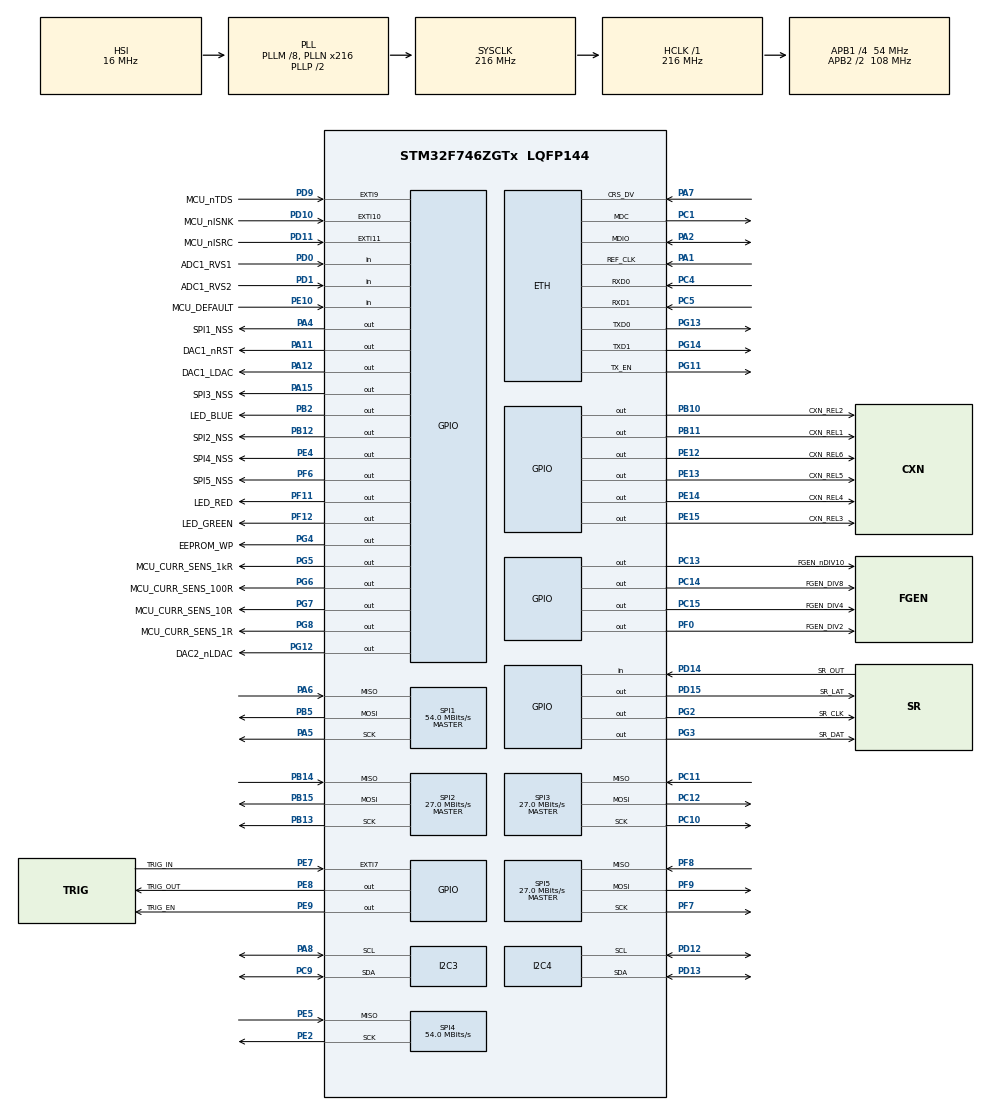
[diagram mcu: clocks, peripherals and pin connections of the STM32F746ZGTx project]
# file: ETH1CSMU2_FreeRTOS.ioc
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CORTEX_M7.CPU_DCache=Disabled
CORTEX_M7.CPU_ICache=Disabled
CORTEX_M7.MPU_Control=__NULL
Dma.Request0=SPI4_RX
Dma.SPI4_RX.0.Direction=DMA_PERIPH_TO_MEMORY
Dma.SPI4_RX.0.FIFOMode=DMA_FIFOMODE_DISABLE
Dma.SPI4_RX.0.Instance=DMA2_Stream0
Dma.SPI4_RX.0.MemDataAlignment=DMA_MDATAALIGN_HALFWORD
Dma.SPI4_RX.0.MemInc=DMA_MINC_ENABLE
Dma.SPI4_RX.0.Mode=DMA_NORMAL
Dma.SPI4_RX.0.PeriphDataAlignment=DMA_PDATAALIGN_HALFWORD
Dma.SPI4_RX.0.PeriphInc=DMA_PINC_DISABLE
Dma.SPI4_RX.0.Priority=DMA_PRIORITY_HIGH
ETH.MediaInterface=HAL_ETH_RMII_MODE
FREERTOS.Queues01=QueueLED,1,uint8_t,0,Static,QueueLEDBuffer,QueueLEDControlBlock;QueueTrigger,1,uint8_t,0,Dynamic,NULL,NULL
FREERTOS.Tasks01=defaultTask,24,254,StartDefaultTask,Default,NULL,Dynamic,NULL,NULL;LEDTask,8,128,StartLEDTask,Default,NULL,Dynamic,NULL,NULL;TriggerTask,8,254,StartTriggerTask,Default,NULL,Dynamic,NULL,NULL
FREERTOS.configENABLE_FPU=1
FREERTOS.configGENERATE_RUN_TIME_STATS=1
FREERTOS.configMINIMAL_STACK_SIZE=128
FREERTOS.configTIMER_TASK_STACK_DEPTH=254
FREERTOS.configTOTAL_HEAP_SIZE=60000
FREERTOS.configUSE_NEWLIB_REENTRANT=1
FREERTOS.configUSE_STATS_FORMATTING_FUNCTIONS=1
I2C3.Timing=0x20404768
I2C4.Timing=0x20404768
LWIP.BSP.number=1
LWIP.CMSIS_VERSION-Enabled=1
LWIP.DEFAULT_THREAD_STACKSIZE=2048
LWIP.GATEWAY_ADDRESS=192.168.001.001
LWIP.IP_ADDRESS=192.168.001.130
LWIP.LWIP_DBG_MIN_LEVEL=LWIP_DBG_LEVEL_ALL
LWIP.LWIP_DHCP=0
LWIP.MEM_SIZE=3200
LWIP.NETMASK_ADDRESS=255.255.255.000
LWIP.TCPIP_THREAD_STACKSIZE=2048
LWIP.Version=v2.1.2_Cube
LWIP0.BSP.STBoard=false
LWIP0.BSP.api=BSP_COMPONENT_DRIVER
LWIP0.BSP.component=LAN8742
LWIP0.BSP.instance=LAN8742
LWIP0.BSP.name=Driver_PHY
LWIP0.BSP.semaphore=S_LAN8742
LWIP0.BSP.solution=LAN8742
Mcu.Family=STM32F7
Mcu.Name=STM32F746ZGTx
Mcu.Package=LQFP144
NVIC.DMA2_Stream0_IRQn=true\:5\:0\:false\:false\:true\:true\:false\:true\:true
NVIC.ETH_IRQn=true\:5\:0\:false\:false\:true\:true\:false\:true\:true
NVIC.PriorityGroup=NVIC_PRIORITYGROUP_4
NVIC.TIM2_IRQn=true\:0\:0\:true\:false\:true\:false\:false\:true\:true
NVIC.TimeBase=TIM2_IRQn
NVIC.TimeBaseIP=TIM2
PA1.Mode=RMII
PA1.Signal=ETH_REF_CLK
PA11.GPIO_Label=DAC1_nRST
PA11.PinState=GPIO_PIN_SET
PA11.Signal=GPIO_Output
PA12.GPIO_Label=DAC1_LDAC
PA12.Signal=GPIO_Output
PA13.Mode=Serial_Wire
PA13.Signal=SYS_JTMS-SWDIO
PA14.Mode=Serial_Wire
PA14.Signal=SYS_JTCK-SWCLK
PA15.GPIO_Label=SPI3_NSS
PA15.PinState=GPIO_PIN_SET
PA15.Signal=GPIO_Output
PA2.Mode=RMII
PA2.Signal=ETH_MDIO
PA4.GPIO_Label=SPI1_NSS
PA4.PinState=GPIO_PIN_SET
PA4.Signal=GPIO_Output
PA5.GPIO_Speed=GPIO_SPEED_FREQ_HIGH
PA5.Mode=Full_Duplex_Master
PA5.Signal=SPI1_SCK
PA6.GPIO_Speed=GPIO_SPEED_FREQ_HIGH
PA6.Mode=Full_Duplex_Master
PA6.Signal=SPI1_MISO
PA7.Mode=RMII
PA7.Signal=ETH_CRS_DV
PA8.Mode=I2C
PA8.Signal=I2C3_SCL
PB10.GPIO_Label=CXN_REL2
PB10.GPIO_Speed=GPIO_SPEED_FREQ_MEDIUM
PB10.PinState=GPIO_PIN_RESET
PB10.Signal=GPIO_Output
PB11.GPIO_Label=CXN_REL1
PB11.GPIO_Speed=GPIO_SPEED_FREQ_MEDIUM
PB11.PinState=GPIO_PIN_RESET
PB11.Signal=GPIO_Output
PB12.GPIO_Label=SPI2_NSS
PB12.PinState=GPIO_PIN_SET
PB12.Signal=GPIO_Output
PB13.Mode=Full_Duplex_Master
PB13.Signal=SPI2_SCK
PB14.Mode=Full_Duplex_Master
PB14.Signal=SPI2_MISO
PB15.Mode=Full_Duplex_Master
PB15.Signal=SPI2_MOSI
PB2.GPIO_Label=LED_BLUE
PB2.PinState=GPIO_PIN_SET
PB2.Signal=GPIO_Output
PB5.GPIO_Speed=GPIO_SPEED_FREQ_HIGH
PB5.Mode=Full_Duplex_Master
PB5.Signal=SPI1_MOSI
PC1.Mode=RMII
PC1.Signal=ETH_MDC
PC10.GPIO_PuPd=GPIO_PULLUP
PC10.GPIO_Speed=GPIO_SPEED_FREQ_HIGH
PC10.Mode=Full_Duplex_Master
PC10.Signal=SPI3_SCK
PC11.GPIO_Speed=GPIO_SPEED_FREQ_HIGH
PC11.Mode=Full_Duplex_Master
PC11.Signal=SPI3_MISO
PC12.GPIO_Speed=GPIO_SPEED_FREQ_HIGH
PC12.Mode=Full_Duplex_Master
PC12.Signal=SPI3_MOSI
PC13.GPIO_Label=FGEN_nDIV10
PC13.PinState=GPIO_PIN_SET
PC13.Signal=GPIO_Output
PC14/OSC32_IN.GPIO_Label=FGEN_DIV8
PC14/OSC32_IN.PinState=GPIO_PIN_SET
PC14/OSC32_IN.Signal=GPIO_Output
PC15/OSC32_OUT.GPIO_Label=FGEN_DIV4
PC15/OSC32_OUT.PinState=GPIO_PIN_SET
PC15/OSC32_OUT.Signal=GPIO_Output
PC4.Mode=RMII
PC4.Signal=ETH_RXD0
PC5.Mode=RMII
PC5.Signal=ETH_RXD1
PC9.Mode=I2C
PC9.Signal=I2C3_SDA
PD0.GPIO_Label=ADC1_RVS1
PD0.Signal=GPIO_Input
PD1.GPIO_Label=ADC1_RVS2
PD1.Signal=GPIO_Input
PD10.GPIO_Label=MCU_nISNK
PD10.Signal=GPXTI10
PD11.GPIO_Label=MCU_nISRC
PD11.Signal=GPXTI11
PD12.Mode=I2C
PD12.Signal=I2C4_SCL
PD13.Mode=I2C
PD13.Signal=I2C4_SDA
PD14.GPIO_Label=SR_OUT
PD14.Signal=GPIO_Input
PD15.GPIO_Label=SR_LAT
PD15.Signal=GPIO_Output
PD9.GPIO_Label=MCU_nTDS
PD9.Signal=GPXTI9
PE10.GPIO_Label=MCU_DEFAULT
PE10.Signal=GPIO_Input
PE12.GPIO_Label=CXN_REL6
PE12.GPIO_Speed=GPIO_SPEED_FREQ_MEDIUM
PE12.Signal=GPIO_Output
PE13.GPIO_Label=CXN_REL5
PE13.GPIO_Speed=GPIO_SPEED_FREQ_MEDIUM
PE13.Signal=GPIO_Output
PE14.GPIO_Label=CXN_REL4
PE14.GPIO_Speed=GPIO_SPEED_FREQ_MEDIUM
PE14.Signal=GPIO_Output
PE15.GPIO_Label=CXN_REL3
PE15.GPIO_Speed=GPIO_SPEED_FREQ_MEDIUM
PE15.Signal=GPIO_Output
PE2.Mode=RX_Only_Simplex_Unidirect_Master
PE2.Signal=SPI4_SCK
PE4.GPIO_Label=SPI4_NSS
PE4.PinState=GPIO_PIN_RESET
PE4.Signal=GPIO_Output
PE5.Mode=RX_Only_Simplex_Unidirect_Master
PE5.Signal=SPI4_MISO
PE7.GPIO_Label=TRIG_IN
PE7.Signal=GPXTI7
PE8.GPIO_Label=TRIG_OUT
PE8.Signal=GPIO_Output
PE9.GPIO_Label=TRIG_EN
PE9.Signal=GPIO_Output
PF0.GPIO_Label=FGEN_DIV2
PF0.PinState=GPIO_PIN_SET
PF0.Signal=GPIO_Output
PF11.GPIO_Label=LED_RED
PF11.PinState=GPIO_PIN_SET
PF11.Signal=GPIO_Output
PF12.GPIO_Label=LED_GREEN
PF12.PinState=GPIO_PIN_SET
PF12.Signal=GPIO_Output
PF6.GPIO_Label=SPI5_NSS
PF6.GPIO_Speed=GPIO_SPEED_FREQ_HIGH
PF6.PinState=GPIO_PIN_SET
PF6.Signal=GPIO_Output
PF7.Mode=Full_Duplex_Master
PF7.Signal=SPI5_SCK
PF8.Mode=Full_Duplex_Master
PF8.Signal=SPI5_MISO
PF9.Mode=Full_Duplex_Master
PF9.Signal=SPI5_MOSI
PG11.Mode=RMII
PG11.Signal=ETH_TX_EN
PG12.GPIO_Label=DAC2_nLDAC
PG12.GPIO_Speed=GPIO_SPEED_FREQ_HIGH
PG12.PinState=GPIO_PIN_SET
PG12.Signal=GPIO_Output
PG13.Mode=RMII
PG13.Signal=ETH_TXD0
PG14.Mode=RMII
PG14.Signal=ETH_TXD1
PG2.GPIO_Label=SR_CLK
PG2.Signal=GPIO_Output
PG3.GPIO_Label=SR_DAT
PG3.Signal=GPIO_Output
PG4.GPIO_Label=EEPROM_WP
PG4.PinState=GPIO_PIN_SET
PG4.Signal=GPIO_Output
PG5.GPIO_Label=MCU_CURR_SENS_1kR
PG5.Signal=GPIO_Output
PG6.GPIO_Label=MCU_CURR_SENS_100R
PG6.PinState=GPIO_PIN_RESET
PG6.Signal=GPIO_Output
PG7.GPIO_Label=MCU_CURR_SENS_10R
PG7.PinState=GPIO_PIN_RESET
PG7.Signal=GPIO_Output
PG8.GPIO_Label=MCU_CURR_SENS_1R
PG8.PinState=GPIO_PIN_SET
PG8.Signal=GPIO_Output
ProjectManager.HeapSize=0x200
ProjectManager.StackSize=0x400
ProjectManager.TargetToolchain=STM32CubeIDE
RCC.AHBFreq_Value=216000000
RCC.APB1CLKDivider=RCC_HCLK_DIV4
RCC.APB1Freq_Value=54000000
RCC.APB1TimFreq_Value=108000000
RCC.APB2CLKDivider=RCC_HCLK_DIV2
RCC.APB2Freq_Value=108000000
RCC.APB2TimFreq_Value=216000000
RCC.CortexFreq_Value=216000000
RCC.HCLKFreq_Value=216000000
RCC.HSE_VALUE=8000000
RCC.HSI_VALUE=16000000
RCC.LSE_VALUE=32768
RCC.PLLM=8
RCC.PLLN=216
RCC.SYSCLKFreq_VALUE=216000000
RCC.SYSCLKSource=RCC_SYSCLKSOURCE_PLLCLK
RCC.USBFreq_Value=216000000
RCC.VCOOutputFreq_Value=432000000
SPI1.BaudRatePrescaler=SPI_BAUDRATEPRESCALER_2
SPI1.CLKPolarity=SPI_POLARITY_LOW
SPI1.CalculateBaudRate=54.0 MBits/s
SPI1.DataSize=SPI_DATASIZE_16BIT
SPI1.Direction=SPI_DIRECTION_2LINES
SPI1.Mode=SPI_MODE_MASTER
SPI1.VirtualType=VM_MASTER
SPI2.BaudRatePrescaler=SPI_BAUDRATEPRESCALER_2
SPI2.CLKPhase=SPI_PHASE_1EDGE
SPI2.CLKPolarity=SPI_POLARITY_HIGH
SPI2.CalculateBaudRate=27.0 MBits/s
SPI2.DataSize=SPI_DATASIZE_8BIT
SPI2.Direction=SPI_DIRECTION_2LINES
SPI2.Mode=SPI_MODE_MASTER
SPI2.VirtualType=VM_MASTER
SPI3.BaudRatePrescaler=SPI_BAUDRATEPRESCALER_2
SPI3.CLKPolarity=SPI_POLARITY_HIGH
SPI3.CalculateBaudRate=27.0 MBits/s
SPI3.DataSize=SPI_DATASIZE_16BIT
SPI3.Direction=SPI_DIRECTION_2LINES
SPI3.Mode=SPI_MODE_MASTER
SPI3.VirtualType=VM_MASTER
SPI4.BaudRatePrescaler=SPI_BAUDRATEPRESCALER_2
SPI4.CLKPhase=SPI_PHASE_1EDGE
SPI4.CalculateBaudRate=54.0 MBits/s
SPI4.DataSize=SPI_DATASIZE_16BIT
SPI4.Direction=SPI_DIRECTION_2LINES_RXONLY
SPI4.Mode=SPI_MODE_MASTER
SPI4.VirtualType=VM_MASTER
SPI5.BaudRatePrescaler=SPI_BAUDRATEPRESCALER_4
SPI5.CalculateBaudRate=27.0 MBits/s
SPI5.DataSize=SPI_DATASIZE_16BIT
SPI5.Direction=SPI_DIRECTION_2LINES
SPI5.Mode=SPI_MODE_MASTER
SPI5.VirtualType=VM_MASTER
TIM3.Period=0xffff -1
TIM3.Prescaler=216 -1
VP_FREERTOS_VS_CMSIS_V2.Mode=CMSIS_V2
VP_LWIP_VS_Enabled.Mode=Enabled
VP_SYS_VS_tim2.Mode=TIM2
VP_TIM3_VS_ClockSourceINT.Mode=Internal
board=custom

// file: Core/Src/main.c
/* USER CODE BEGIN Header */
/**
  ******************************************************************************
  * @file           : main.c
  * @brief          : Main program body
  ******************************************************************************
  * @attention
  *
  * Copyright (c) 2022 STMicroelectronics.
  * All rights reserved.
  *
  * This software is licensed under terms that can be found in the LICENSE file
  * in the root directory of this software component.
  * If no LICENSE file comes with this software, it is provided AS-IS.
  *
  ******************************************************************************
  */
/* USER CODE END Header */
#include "main.h"
#include "cmsis_os.h"
#include "lwip.h"

/* USER CODE BEGIN Includes */
#include "LED.h"
#include "74HC595.h"
#include "AD9834.h"
#include "MAX5217.h"
#include "DAC8565.h"
#include "ADS8681.h"
#include "FGEN.h"
#include "SCPI_Server.h"
#include "Delay.h"
/* USER CODE END Includes */

typedef StaticQueue_t osStaticMessageQDef_t;

I2C_HandleTypeDef hi2c3;
I2C_HandleTypeDef hi2c4;

SPI_HandleTypeDef hspi1;
SPI_HandleTypeDef hspi2;
SPI_HandleTypeDef hspi3;
SPI_HandleTypeDef hspi4;
SPI_HandleTypeDef hspi5;
DMA_HandleTypeDef hdma_spi4_rx;

TIM_HandleTypeDef htim3;

/* Definitions for defaultTask */
osThreadId_t defaultTaskHandle;
const osThreadAttr_t defaultTask_attributes = {
  .name = "defaultTask",
  .stack_size = 254 * 4,
  .priority = (osPriority_t) osPriorityNormal,
};
/* Definitions for LEDTask */
osThreadId_t LEDTaskHandle;
const osThreadAttr_t LEDTask_attributes = {
  .name = "LEDTask",
  .stack_size = 128 * 4,
  .priority = (osPriority_t) osPriorityLow,
};
/* Definitions for TriggerTask */
osThreadId_t TriggerTaskHandle;
const osThreadAttr_t TriggerTask_attributes = {
  .name = "TriggerTask",
  .stack_size = 254 * 4,
  .priority = (osPriority_t) osPriorityLow,
};
/* Definitions for QueueLED */
osMessageQueueId_t QueueLEDHandle;
uint8_t QueueLEDBuffer[ 1 * sizeof( uint8_t ) ];
osStaticMessageQDef_t QueueLEDControlBlock;
const osMessageQueueAttr_t QueueLED_attributes = {
  .name = "QueueLED",
  .cb_mem = &QueueLEDControlBlock,
  .cb_size = sizeof(QueueLEDControlBlock),
  .mq_mem = &QueueLEDBuffer,
  .mq_size = sizeof(QueueLEDBuffer)
};
/* Definitions for QueueTrigger */
osMessageQueueId_t QueueTriggerHandle;
const osMessageQueueAttr_t QueueTrigger_attributes = {
  .name = "QueueTrigger"
};
/* USER CODE BEGIN PV */
extern uint8_t shiftRegisters[];
extern struct bsp_t bsp;
/* USER CODE END PV */

void SystemClock_Config(void);
static void MX_GPIO_Init(void);
static void MX_DMA_Init(void);
static void MX_SPI3_Init(void);
static void MX_SPI4_Init(void);
static void MX_SPI5_Init(void);
static void MX_I2C3_Init(void);
static void MX_I2C4_Init(void);
static void MX_SPI1_Init(void);
static void MX_SPI2_Init(void);
static void MX_TIM3_Init(void);
void StartDefaultTask(void *argument);
void StartLEDTask(void *argument);
void StartTriggerTask(void *argument);

int main(void)
{

  /* MCU Configuration--------------------------------------------------------*/

  /* Reset of all peripherals, Initializes the Flash interface and the Systick. */
  HAL_Init();

  /* Configure the system clock */
  SystemClock_Config();

  /* Initialize all configured peripherals */
  MX_GPIO_Init();
  SN74HC595_Init();
  MX_DMA_Init();
  MX_SPI3_Init();
  MX_SPI4_Init();
  MX_SPI5_Init();
  MX_I2C3_Init();
  MX_I2C4_Init();
  MX_SPI1_Init();
  MX_SPI2_Init();
  MX_TIM3_Init();
  /* USER CODE BEGIN 2 */
  DAC8565_Init();
  TIM_DelayInit();
  BSP_Init();
  //SN74HC595_Init();
  MAX5217_Init();
  ADS8681_Init();
  FGEN_Init();

  TIM_DelayInit();
//  AD9834_Init();
  /* USER CODE END 2 */

  /* Init scheduler */
  osKernelInitialize();

  /* Create the queue(s) */
  /* creation of QueueLED */
  QueueLEDHandle = osMessageQueueNew (1, sizeof(uint8_t), &QueueLED_attributes);

  /* creation of QueueTrigger */
  QueueTriggerHandle = osMessageQueueNew (1, sizeof(uint8_t), &QueueTrigger_attributes);

  /* Create the thread(s) */
  /* creation of defaultTask */
 // defaultTaskHandle = osThreadNew(StartDefaultTask, NULL, &defaultTask_attributes);

  /* creation of LEDTask */
  LEDTaskHandle = osThreadNew(StartLEDTask, NULL, &LEDTask_attributes);

  /* creation of TriggerTask */
  TriggerTaskHandle = osThreadNew(StartTriggerTask, NULL, &TriggerTask_attributes);

  /* USER CODE BEGIN RTOS_THREADS */
  /* add threads, ... */
  MX_LWIP_Init();
  scpi_server_init();
  /* USER CODE END RTOS_THREADS */

  /* Start scheduler */
  osKernelStart();
  /* We should never get here as control is now taken by the scheduler */
  /* Infinite loop */
  while (1)
  {

  }
}

void SystemClock_Config(void)
{
  RCC_OscInitTypeDef RCC_OscInitStruct = {0};
  RCC_ClkInitTypeDef RCC_ClkInitStruct = {0};

  /** Configure the main internal regulator output voltage
  */
  __HAL_RCC_PWR_CLK_ENABLE();
  __HAL_PWR_VOLTAGESCALING_CONFIG(PWR_REGULATOR_VOLTAGE_SCALE1);

  /** Initializes the RCC Oscillators according to the specified parameters
  * in the RCC_OscInitTypeDef structure.
  */
  RCC_OscInitStruct.OscillatorType = RCC_OSCILLATORTYPE_HSI;
  RCC_OscInitStruct.HSIState = RCC_HSI_ON;
  RCC_OscInitStruct.HSICalibrationValue = RCC_HSICALIBRATION_DEFAULT;
  RCC_OscInitStruct.PLL.PLLState = RCC_PLL_ON;
  RCC_OscInitStruct.PLL.PLLSource = RCC_PLLSOURCE_HSI;
  RCC_OscInitStruct.PLL.PLLM = 8;
  RCC_OscInitStruct.PLL.PLLN = 216;
  RCC_OscInitStruct.PLL.PLLP = RCC_PLLP_DIV2;
  RCC_OscInitStruct.PLL.PLLQ = 2;
  if (HAL_RCC_OscConfig(&RCC_OscInitStruct) != HAL_OK)
  {
    Error_Handler();
  }

  /** Activate the Over-Drive mode
  */
  if (HAL_PWREx_EnableOverDrive() != HAL_OK)
  {
    Error_Handler();
  }

  /** Initializes the CPU, AHB and APB buses clocks
  */
  RCC_ClkInitStruct.ClockType = RCC_CLOCKTYPE_HCLK|RCC_CLOCKTYPE_SYSCLK
                              |RCC_CLOCKTYPE_PCLK1|RCC_CLOCKTYPE_PCLK2;
  RCC_ClkInitStruct.SYSCLKSource = RCC_SYSCLKSOURCE_PLLCLK;
  RCC_ClkInitStruct.AHBCLKDivider = RCC_SYSCLK_DIV1;
  RCC_ClkInitStruct.APB1CLKDivider = RCC_HCLK_DIV4;
  RCC_ClkInitStruct.APB2CLKDivider = RCC_HCLK_DIV2;

  if (HAL_RCC_ClockConfig(&RCC_ClkInitStruct, FLASH_LATENCY_7) != HAL_OK)
  {
    Error_Handler();
  }
}

static void MX_I2C3_Init(void)
{

  hi2c3.Instance = I2C3;
  hi2c3.Init.Timing = 0x20404768;
  hi2c3.Init.OwnAddress1 = 0;
  hi2c3.Init.AddressingMode = I2C_ADDRESSINGMODE_7BIT;
  hi2c3.Init.DualAddressMode = I2C_DUALADDRESS_DISABLE;
  hi2c3.Init.OwnAddress2 = 0;
  hi2c3.Init.OwnAddress2Masks = I2C_OA2_NOMASK;
  hi2c3.Init.GeneralCallMode = I2C_GENERALCALL_DISABLE;
  hi2c3.Init.NoStretchMode = I2C_NOSTRETCH_DISABLE;
  if (HAL_I2C_Init(&hi2c3) != HAL_OK)
  {
    Error_Handler();
  }

  /** Configure Analogue filter
  */
  if (HAL_I2CEx_ConfigAnalogFilter(&hi2c3, I2C_ANALOGFILTER_ENABLE) != HAL_OK)
  {
    Error_Handler();
  }

  /** Configure Digital filter
  */
  if (HAL_I2CEx_ConfigDigitalFilter(&hi2c3, 0) != HAL_OK)
  {
    Error_Handler();
  }

}

static void MX_I2C4_Init(void)
{

  hi2c4.Instance = I2C4;
  hi2c4.Init.Timing = 0x20404768;
  hi2c4.Init.OwnAddress1 = 0;
  hi2c4.Init.AddressingMode = I2C_ADDRESSINGMODE_7BIT;
  hi2c4.Init.DualAddressMode = I2C_DUALADDRESS_DISABLE;
  hi2c4.Init.OwnAddress2 = 0;
  hi2c4.Init.OwnAddress2Masks = I2C_OA2_NOMASK;
  hi2c4.Init.GeneralCallMode = I2C_GENERALCALL_DISABLE;
  hi2c4.Init.NoStretchMode = I2C_NOSTRETCH_DISABLE;
  if (HAL_I2C_Init(&hi2c4) != HAL_OK)
  {
    Error_Handler();
  }

  /** Configure Analogue filter
  */
  if (HAL_I2CEx_ConfigAnalogFilter(&hi2c4, I2C_ANALOGFILTER_ENABLE) != HAL_OK)
  {
    Error_Handler();
  }

  /** Configure Digital filter
  */
  if (HAL_I2CEx_ConfigDigitalFilter(&hi2c4, 0) != HAL_OK)
  {
    Error_Handler();
  }

}

static void MX_SPI1_Init(void)
{

  /* SPI1 parameter configuration*/
  hspi1.Instance = SPI1;
  hspi1.Init.Mode = SPI_MODE_MASTER;
  hspi1.Init.Direction = SPI_DIRECTION_2LINES;
  hspi1.Init.DataSize = SPI_DATASIZE_16BIT;
  hspi1.Init.CLKPolarity = SPI_POLARITY_LOW;
  hspi1.Init.CLKPhase = SPI_PHASE_1EDGE;
  hspi1.Init.NSS = SPI_NSS_SOFT;
  hspi1.Init.BaudRatePrescaler = SPI_BAUDRATEPRESCALER_2;
  hspi1.Init.FirstBit = SPI_FIRSTBIT_MSB;
  hspi1.Init.TIMode = SPI_TIMODE_DISABLE;
  hspi1.Init.CRCCalculation = SPI_CRCCALCULATION_DISABLE;
  hspi1.Init.CRCPolynomial = 7;
  hspi1.Init.CRCLength = SPI_CRC_LENGTH_DATASIZE;
  hspi1.Init.NSSPMode = SPI_NSS_PULSE_ENABLE;
  if (HAL_SPI_Init(&hspi1) != HAL_OK)
  {
    Error_Handler();
  }

}

static void MX_SPI2_Init(void)
{

  /* SPI2 parameter configuration*/
  hspi2.Instance = SPI2;
  hspi2.Init.Mode = SPI_MODE_MASTER;
  hspi2.Init.Direction = SPI_DIRECTION_2LINES;
  hspi2.Init.DataSize = SPI_DATASIZE_8BIT;
  hspi2.Init.CLKPolarity = SPI_POLARITY_HIGH;
  hspi2.Init.CLKPhase = SPI_PHASE_1EDGE;
  hspi2.Init.NSS = SPI_NSS_SOFT;
  hspi2.Init.BaudRatePrescaler = SPI_BAUDRATEPRESCALER_2;
  hspi2.Init.FirstBit = SPI_FIRSTBIT_MSB;
  hspi2.Init.TIMode = SPI_TIMODE_DISABLE;
  hspi2.Init.CRCCalculation = SPI_CRCCALCULATION_DISABLE;
  hspi2.Init.CRCPolynomial = 7;
  hspi2.Init.CRCLength = SPI_CRC_LENGTH_DATASIZE;
  hspi2.Init.NSSPMode = SPI_NSS_PULSE_ENABLE;
  if (HAL_SPI_Init(&hspi2) != HAL_OK)
  {
    Error_Handler();
  }

}

static void MX_SPI3_Init(void)
{

  /* SPI3 parameter configuration*/
  hspi3.Instance = SPI3;
  hspi3.Init.Mode = SPI_MODE_MASTER;
  hspi3.Init.Direction = SPI_DIRECTION_2LINES;
  hspi3.Init.DataSize = SPI_DATASIZE_16BIT;
  hspi3.Init.CLKPolarity = SPI_POLARITY_HIGH;
  hspi3.Init.CLKPhase = SPI_PHASE_1EDGE;
  hspi3.Init.NSS = SPI_NSS_SOFT;
  hspi3.Init.BaudRatePrescaler = SPI_BAUDRATEPRESCALER_2;
  hspi3.Init.FirstBit = SPI_FIRSTBIT_MSB;
  hspi3.Init.TIMode = SPI_TIMODE_DISABLE;
  hspi3.Init.CRCCalculation = SPI_CRCCALCULATION_DISABLE;
  hspi3.Init.CRCPolynomial = 7;
  hspi3.Init.CRCLength = SPI_CRC_LENGTH_DATASIZE;
  hspi3.Init.NSSPMode = SPI_NSS_PULSE_ENABLE;
  if (HAL_SPI_Init(&hspi3) != HAL_OK)
  {
    Error_Handler();
  }

}

static void MX_SPI4_Init(void)
{

  /* SPI4 parameter configuration*/
  hspi4.Instance = SPI4;
  hspi4.Init.Mode = SPI_MODE_MASTER;
  hspi4.Init.Direction = SPI_DIRECTION_2LINES_RXONLY;
  hspi4.Init.DataSize = SPI_DATASIZE_16BIT;
  hspi4.Init.CLKPolarity = SPI_POLARITY_LOW;
  hspi4.Init.CLKPhase = SPI_PHASE_1EDGE;
  hspi4.Init.NSS = SPI_NSS_SOFT;
  hspi4.Init.BaudRatePrescaler = SPI_BAUDRATEPRESCALER_2;
  hspi4.Init.FirstBit = SPI_FIRSTBIT_MSB;
  hspi4.Init.TIMode = SPI_TIMODE_DISABLE;
  hspi4.Init.CRCCalculation = SPI_CRCCALCULATION_DISABLE;
  hspi4.Init.CRCPolynomial = 7;
  hspi4.Init.CRCLength = SPI_CRC_LENGTH_DATASIZE;
  hspi4.Init.NSSPMode = SPI_NSS_PULSE_ENABLE;
  if (HAL_SPI_Init(&hspi4) != HAL_OK)
  {
    Error_Handler();
  }

}

static void MX_SPI5_Init(void)
{

  /* SPI5 parameter configuration*/
  hspi5.Instance = SPI5;
  hspi5.Init.Mode = SPI_MODE_MASTER;
  hspi5.Init.Direction = SPI_DIRECTION_2LINES;
  hspi5.Init.DataSize = SPI_DATASIZE_16BIT;
  hspi5.Init.CLKPolarity = SPI_POLARITY_LOW;
  hspi5.Init.CLKPhase = SPI_PHASE_1EDGE;
  hspi5.Init.NSS = SPI_NSS_SOFT;
  hspi5.Init.BaudRatePrescaler = SPI_BAUDRATEPRESCALER_4;
  hspi5.Init.FirstBit = SPI_FIRSTBIT_MSB;
  hspi5.Init.TIMode = SPI_TIMODE_DISABLE;
  hspi5.Init.CRCCalculation = SPI_CRCCALCULATION_DISABLE;
  hspi5.Init.CRCPolynomial = 7;
  hspi5.Init.CRCLength = SPI_CRC_LENGTH_DATASIZE;
  hspi5.Init.NSSPMode = SPI_NSS_PULSE_ENABLE;
  if (HAL_SPI_Init(&hspi5) != HAL_OK)
  {
    Error_Handler();
  }

}

static void MX_TIM3_Init(void)
{

  TIM_ClockConfigTypeDef sClockSourceConfig = {0};
  TIM_MasterConfigTypeDef sMasterConfig = {0};

  htim3.Instance = TIM3;
  htim3.Init.Prescaler = 216 -1;
  htim3.Init.CounterMode = TIM_COUNTERMODE_UP;
  htim3.Init.Period = 0xffff -1;
  htim3.Init.ClockDivision = TIM_CLOCKDIVISION_DIV1;
  htim3.Init.AutoReloadPreload = TIM_AUTORELOAD_PRELOAD_DISABLE;
  if (HAL_TIM_Base_Init(&htim3) != HAL_OK)
  {
    Error_Handler();
  }
  sClockSourceConfig.ClockSource = TIM_CLOCKSOURCE_INTERNAL;
  if (HAL_TIM_ConfigClockSource(&htim3, &sClockSourceConfig) != HAL_OK)
  {
    Error_Handler();
  }
  sMasterConfig.MasterOutputTrigger = TIM_TRGO_RESET;
  sMasterConfig.MasterSlaveMode = TIM_MASTERSLAVEMODE_DISABLE;
  if (HAL_TIMEx_MasterConfigSynchronization(&htim3, &sMasterConfig) != HAL_OK)
  {
    Error_Handler();
  }

}

static void MX_DMA_Init(void)
{

  /* DMA controller clock enable */
  __HAL_RCC_DMA2_CLK_ENABLE();

  /* DMA interrupt init */
  /* DMA2_Stream0_IRQn interrupt configuration */
  HAL_NVIC_SetPriority(DMA2_Stream0_IRQn, 5, 0);
  HAL_NVIC_EnableIRQ(DMA2_Stream0_IRQn);

}

static void MX_GPIO_Init(void)
{
  LL_EXTI_InitTypeDef EXTI_InitStruct = {0};
  LL_GPIO_InitTypeDef GPIO_InitStruct = {0};

  /* GPIO Ports Clock Enable */
  LL_AHB1_GRP1_EnableClock(LL_AHB1_GRP1_PERIPH_GPIOE);
  LL_AHB1_GRP1_EnableClock(LL_AHB1_GRP1_PERIPH_GPIOC);
  LL_AHB1_GRP1_EnableClock(LL_AHB1_GRP1_PERIPH_GPIOF);
  LL_AHB1_GRP1_EnableClock(LL_AHB1_GRP1_PERIPH_GPIOA);
  LL_AHB1_GRP1_EnableClock(LL_AHB1_GRP1_PERIPH_GPIOB);
  LL_AHB1_GRP1_EnableClock(LL_AHB1_GRP1_PERIPH_GPIOD);
  LL_AHB1_GRP1_EnableClock(LL_AHB1_GRP1_PERIPH_GPIOG);

  /**/
  LL_GPIO_ResetOutputPin(SPI4_NSS_GPIO_Port, SPI4_NSS_Pin);

  /**/
  LL_GPIO_ResetOutputPin(TRIG_OUT_GPIO_Port, TRIG_OUT_Pin);

  /**/
  LL_GPIO_ResetOutputPin(TRIG_EN_GPIO_Port, TRIG_EN_Pin);

  /**/
  LL_GPIO_ResetOutputPin(CXN_REL6_GPIO_Port, CXN_REL6_Pin);

  /**/
  LL_GPIO_ResetOutputPin(CXN_REL5_GPIO_Port, CXN_REL5_Pin);

  /**/
  LL_GPIO_ResetOutputPin(CXN_REL4_GPIO_Port, CXN_REL4_Pin);

  /**/
  LL_GPIO_ResetOutputPin(CXN_REL3_GPIO_Port, CXN_REL3_Pin);

  /**/
  LL_GPIO_ResetOutputPin(CXN_REL2_GPIO_Port, CXN_REL2_Pin);

  /**/
  LL_GPIO_ResetOutputPin(CXN_REL1_GPIO_Port, CXN_REL1_Pin);

  /**/
  LL_GPIO_ResetOutputPin(SR_LAT_GPIO_Port, SR_LAT_Pin);

  /**/
  LL_GPIO_ResetOutputPin(SR_CLK_GPIO_Port, SR_CLK_Pin);

  /**/
  LL_GPIO_ResetOutputPin(SR_DAT_GPIO_Port, SR_DAT_Pin);

  /**/
  LL_GPIO_ResetOutputPin(MCU_CURR_SENS_1kR_GPIO_Port, MCU_CURR_SENS_1kR_Pin);

  /**/
  LL_GPIO_ResetOutputPin(MCU_CURR_SENS_100R_GPIO_Port, MCU_CURR_SENS_100R_Pin);

  /**/
  LL_GPIO_ResetOutputPin(MCU_CURR_SENS_10R_GPIO_Port, MCU_CURR_SENS_10R_Pin);

  /**/
  LL_GPIO_ResetOutputPin(DAC1_LDAC_GPIO_Port, DAC1_LDAC_Pin);

  /**/
  LL_GPIO_SetOutputPin(FGEN_nDIV10_GPIO_Port, FGEN_nDIV10_Pin);

  /**/
  LL_GPIO_SetOutputPin(FGEN_DIV8_GPIO_Port, FGEN_DIV8_Pin);

  /**/
  LL_GPIO_SetOutputPin(FGEN_DIV4_GPIO_Port, FGEN_DIV4_Pin);

  /**/
  LL_GPIO_SetOutputPin(FGEN_DIV2_GPIO_Port, FGEN_DIV2_Pin);

  /**/
  LL_GPIO_SetOutputPin(SPI5_NSS_GPIO_Port, SPI5_NSS_Pin);

  /**/
  LL_GPIO_SetOutputPin(SPI1_NSS_GPIO_Port, SPI1_NSS_Pin);

  /**/
  LL_GPIO_SetOutputPin(LED_BLUE_GPIO_Port, LED_BLUE_Pin);

  /**/
  LL_GPIO_SetOutputPin(LED_RED_GPIO_Port, LED_RED_Pin);

  /**/
  LL_GPIO_SetOutputPin(LED_GREEN_GPIO_Port, LED_GREEN_Pin);

  /**/
  LL_GPIO_SetOutputPin(SPI2_NSS_GPIO_Port, SPI2_NSS_Pin);

  /**/
  LL_GPIO_SetOutputPin(EEPROM_WP_GPIO_Port, EEPROM_WP_Pin);

  /**/
  LL_GPIO_SetOutputPin(MCU_CURR_SENS_1R_GPIO_Port, MCU_CURR_SENS_1R_Pin);

  /**/
  LL_GPIO_SetOutputPin(DAC1_nRST_GPIO_Port, DAC1_nRST_Pin);

  /**/
  LL_GPIO_SetOutputPin(SPI3_NSS_GPIO_Port, SPI3_NSS_Pin);

  /**/
  LL_GPIO_SetOutputPin(DAC2_nLDAC_GPIO_Port, DAC2_nLDAC_Pin);

  /**/
  GPIO_InitStruct.Pin = SPI4_NSS_Pin;
  GPIO_InitStruct.Mode = LL_GPIO_MODE_OUTPUT;
  GPIO_InitStruct.Speed = LL_GPIO_SPEED_FREQ_LOW;
  GPIO_InitStruct.OutputType = LL_GPIO_OUTPUT_PUSHPULL;
  GPIO_InitStruct.Pull = LL_GPIO_PULL_NO;
  LL_GPIO_Init(SPI4_NSS_GPIO_Port, &GPIO_InitStruct);

  /**/
  GPIO_InitStruct.Pin = FGEN_nDIV10_Pin;
  GPIO_InitStruct.Mode = LL_GPIO_MODE_OUTPUT;
  GPIO_InitStruct.Speed = LL_GPIO_SPEED_FREQ_LOW;
  GPIO_InitStruct.OutputType = LL_GPIO_OUTPUT_PUSHPULL;
  GPIO_InitStruct.Pull = LL_GPIO_PULL_NO;
  LL_GPIO_Init(FGEN_nDIV10_GPIO_Port, &GPIO_InitStruct);

  /**/
  GPIO_InitStruct.Pin = FGEN_DIV8_Pin;
  GPIO_InitStruct.Mode = LL_GPIO_MODE_OUTPUT;
  GPIO_InitStruct.Speed = LL_GPIO_SPEED_FREQ_LOW;
  GPIO_InitStruct.OutputType = LL_GPIO_OUTPUT_PUSHPULL;
  GPIO_InitStruct.Pull = LL_GPIO_PULL_NO;
  LL_GPIO_Init(FGEN_DIV8_GPIO_Port, &GPIO_InitStruct);

  /**/
  GPIO_InitStruct.Pin = FGEN_DIV4_Pin;
  GPIO_InitStruct.Mode = LL_GPIO_MODE_OUTPUT;
  GPIO_InitStruct.Speed = LL_GPIO_SPEED_FREQ_LOW;
  GPIO_InitStruct.OutputType = LL_GPIO_OUTPUT_PUSHPULL;
  GPIO_InitStruct.Pull = LL_GPIO_PULL_NO;
  LL_GPIO_Init(FGEN_DIV4_GPIO_Port, &GPIO_InitStruct);

  /**/
  GPIO_InitStruct.Pin = FGEN_DIV2_Pin;
  GPIO_InitStruct.Mode = LL_GPIO_MODE_OUTPUT;
  GPIO_InitStruct.Speed = LL_GPIO_SPEED_FREQ_LOW;
  GPIO_InitStruct.OutputType = LL_GPIO_OUTPUT_PUSHPULL;
  GPIO_InitStruct.Pull = LL_GPIO_PULL_NO;
  LL_GPIO_Init(FGEN_DIV2_GPIO_Port, &GPIO_InitStruct);

  /**/
  GPIO_InitStruct.Pin = SPI5_NSS_Pin;
  GPIO_InitStruct.Mode = LL_GPIO_MODE_OUTPUT;
  GPIO_InitStruct.Speed = LL_GPIO_SPEED_FREQ_HIGH;
  GPIO_InitStruct.OutputType = LL_GPIO_OUTPUT_PUSHPULL;
  GPIO_InitStruct.Pull = LL_GPIO_PULL_NO;
  LL_GPIO_Init(SPI5_NSS_GPIO_Port, &GPIO_InitStruct);

  /**/
  GPIO_InitStruct.Pin = SPI1_NSS_Pin;
  GPIO_InitStruct.Mode = LL_GPIO_MODE_OUTPUT;
  GPIO_InitStruct.Speed = LL_GPIO_SPEED_FREQ_LOW;
  GPIO_InitStruct.OutputType = LL_GPIO_OUTPUT_PUSHPULL;
  GPIO_InitStruct.Pull = LL_GPIO_PULL_NO;
  LL_GPIO_Init(SPI1_NSS_GPIO_Port, &GPIO_InitStruct);

  /**/
  GPIO_InitStruct.Pin = LED_BLUE_Pin;
  GPIO_InitStruct.Mode = LL_GPIO_MODE_OUTPUT;
  GPIO_InitStruct.Speed = LL_GPIO_SPEED_FREQ_LOW;
  GPIO_InitStruct.OutputType = LL_GPIO_OUTPUT_PUSHPULL;
  GPIO_InitStruct.Pull = LL_GPIO_PULL_NO;
  LL_GPIO_Init(LED_BLUE_GPIO_Port, &GPIO_InitStruct);

  /**/
  GPIO_InitStruct.Pin = LED_RED_Pin;
  GPIO_InitStruct.Mode = LL_GPIO_MODE_OUTPUT;
  GPIO_InitStruct.Speed = LL_GPIO_SPEED_FREQ_LOW;
  GPIO_InitStruct.OutputType = LL_GPIO_OUTPUT_PUSHPULL;
  GPIO_InitStruct.Pull = LL_GPIO_PULL_NO;
  LL_GPIO_Init(LED_RED_GPIO_Port, &GPIO_InitStruct);

  /**/
  GPIO_InitStruct.Pin = LED_GREEN_Pin;
  GPIO_InitStruct.Mode = LL_GPIO_MODE_OUTPUT;
  GPIO_InitStruct.Speed = LL_GPIO_SPEED_FREQ_LOW;
  GPIO_InitStruct.OutputType = LL_GPIO_OUTPUT_PUSHPULL;
  GPIO_InitStruct.Pull = LL_GPIO_PULL_NO;
  LL_GPIO_Init(LED_GREEN_GPIO_Port, &GPIO_InitStruct);

  /**/
  GPIO_InitStruct.Pin = TRIG_OUT_Pin;
  GPIO_InitStruct.Mode = LL_GPIO_MODE_OUTPUT;
  GPIO_InitStruct.Speed = LL_GPIO_SPEED_FREQ_LOW;
  GPIO_InitStruct.OutputType = LL_GPIO_OUTPUT_PUSHPULL;
  GPIO_InitStruct.Pull = LL_GPIO_PULL_NO;
  LL_GPIO_Init(TRIG_OUT_GPIO_Port, &GPIO_InitStruct);

  /**/
  GPIO_InitStruct.Pin = TRIG_EN_Pin;
  GPIO_InitStruct.Mode = LL_GPIO_MODE_OUTPUT;
  GPIO_InitStruct.Speed = LL_GPIO_SPEED_FREQ_LOW;
  GPIO_InitStruct.OutputType = LL_GPIO_OUTPUT_PUSHPULL;
  GPIO_InitStruct.Pull = LL_GPIO_PULL_NO;
  LL_GPIO_Init(TRIG_EN_GPIO_Port, &GPIO_InitStruct);

  /**/
  GPIO_InitStruct.Pin = MCU_DEFAULT_Pin;
  GPIO_InitStruct.Mode = LL_GPIO_MODE_INPUT;
  GPIO_InitStruct.Pull = LL_GPIO_PULL_NO;
  LL_GPIO_Init(MCU_DEFAULT_GPIO_Port, &GPIO_InitStruct);

  /**/
  GPIO_InitStruct.Pin = CXN_REL6_Pin;
  GPIO_InitStruct.Mode = LL_GPIO_MODE_OUTPUT;
  GPIO_InitStruct.Speed = LL_GPIO_SPEED_FREQ_MEDIUM;
  GPIO_InitStruct.OutputType = LL_GPIO_OUTPUT_PUSHPULL;
  GPIO_InitStruct.Pull = LL_GPIO_PULL_NO;
  LL_GPIO_Init(CXN_REL6_GPIO_Port, &GPIO_InitStruct);

  /**/
  GPIO_InitStruct.Pin = CXN_REL5_Pin;
  GPIO_InitStruct.Mode = LL_GPIO_MODE_OUTPUT;
  GPIO_InitStruct.Speed = LL_GPIO_SPEED_FREQ_MEDIUM;
  GPIO_InitStruct.OutputType = LL_GPIO_OUTPUT_PUSHPULL;
  GPIO_InitStruct.Pull = LL_GPIO_PULL_NO;
  LL_GPIO_Init(CXN_REL5_GPIO_Port, &GPIO_InitStruct);

  /**/
  GPIO_InitStruct.Pin = CXN_REL4_Pin;
  GPIO_InitStruct.Mode = LL_GPIO_MODE_OUTPUT;
  GPIO_InitStruct.Speed = LL_GPIO_SPEED_FREQ_MEDIUM;
  GPIO_InitStruct.OutputType = LL_GPIO_OUTPUT_PUSHPULL;
  GPIO_InitStruct.Pull = LL_GPIO_PULL_NO;
  LL_GPIO_Init(CXN_REL4_GPIO_Port, &GPIO_InitStruct);

  /**/
  GPIO_InitStruct.Pin = CXN_REL3_Pin;
  GPIO_InitStruct.Mode = LL_GPIO_MODE_OUTPUT;
  GPIO_InitStruct.Speed = LL_GPIO_SPEED_FREQ_MEDIUM;
  GPIO_InitStruct.OutputType = LL_GPIO_OUTPUT_PUSHPULL;
  GPIO_InitStruct.Pull = LL_GPIO_PULL_NO;
  LL_GPIO_Init(CXN_REL3_GPIO_Port, &GPIO_InitStruct);

  /**/
  GPIO_InitStruct.Pin = CXN_REL2_Pin;
  GPIO_InitStruct.Mode = LL_GPIO_MODE_OUTPUT;
  GPIO_InitStruct.Speed = LL_GPIO_SPEED_FREQ_MEDIUM;
  GPIO_InitStruct.OutputType = LL_GPIO_OUTPUT_PUSHPULL;
  GPIO_InitStruct.Pull = LL_GPIO_PULL_NO;
  LL_GPIO_Init(CXN_REL2_GPIO_Port, &GPIO_InitStruct);

  /**/
  GPIO_InitStruct.Pin = CXN_REL1_Pin;
  GPIO_InitStruct.Mode = LL_GPIO_MODE_OUTPUT;
  GPIO_InitStruct.Speed = LL_GPIO_SPEED_FREQ_MEDIUM;
  GPIO_InitStruct.OutputType = LL_GPIO_OUTPUT_PUSHPULL;
  GPIO_InitStruct.Pull = LL_GPIO_PULL_NO;
  LL_GPIO_Init(CXN_REL1_GPIO_Port, &GPIO_InitStruct);

  /**/
  GPIO_InitStruct.Pin = SPI2_NSS_Pin;
  GPIO_InitStruct.Mode = LL_GPIO_MODE_OUTPUT;
  GPIO_InitStruct.Speed = LL_GPIO_SPEED_FREQ_LOW;
  GPIO_InitStruct.OutputType = LL_GPIO_OUTPUT_PUSHPULL;
  GPIO_InitStruct.Pull = LL_GPIO_PULL_NO;
  LL_GPIO_Init(SPI2_NSS_GPIO_Port, &GPIO_InitStruct);

  /**/
  GPIO_InitStruct.Pin = SR_OUT_Pin;
  GPIO_InitStruct.Mode = LL_GPIO_MODE_INPUT;
  GPIO_InitStruct.Pull = LL_GPIO_PULL_NO;
  LL_GPIO_Init(SR_OUT_GPIO_Port, &GPIO_InitStruct);

  /**/
  GPIO_InitStruct.Pin = SR_LAT_Pin;
  GPIO_InitStruct.Mode = LL_GPIO_MODE_OUTPUT;
  GPIO_InitStruct.Speed = LL_GPIO_SPEED_FREQ_LOW;
  GPIO_InitStruct.OutputType = LL_GPIO_OUTPUT_PUSHPULL;
  GPIO_InitStruct.Pull = LL_GPIO_PULL_NO;
  LL_GPIO_Init(SR_LAT_GPIO_Port, &GPIO_InitStruct);

  /**/
  GPIO_InitStruct.Pin = SR_CLK_Pin;
  GPIO_InitStruct.Mode = LL_GPIO_MODE_OUTPUT;
  GPIO_InitStruct.Speed = LL_GPIO_SPEED_FREQ_LOW;
  GPIO_InitStruct.OutputType = LL_GPIO_OUTPUT_PUSHPULL;
  GPIO_InitStruct.Pull = LL_GPIO_PULL_NO;
  LL_GPIO_Init(SR_CLK_GPIO_Port, &GPIO_InitStruct);

  /**/
  GPIO_InitStruct.Pin = SR_DAT_Pin;
  GPIO_InitStruct.Mode = LL_GPIO_MODE_OUTPUT;
  GPIO_InitStruct.Speed = LL_GPIO_SPEED_FREQ_LOW;
  GPIO_InitStruct.OutputType = LL_GPIO_OUTPUT_PUSHPULL;
  GPIO_InitStruct.Pull = LL_GPIO_PULL_NO;
  LL_GPIO_Init(SR_DAT_GPIO_Port, &GPIO_InitStruct);

  /**/
  GPIO_InitStruct.Pin = EEPROM_WP_Pin;
  GPIO_InitStruct.Mode = LL_GPIO_MODE_OUTPUT;
  GPIO_InitStruct.Speed = LL_GPIO_SPEED_FREQ_LOW;
  GPIO_InitStruct.OutputType = LL_GPIO_OUTPUT_PUSHPULL;
  GPIO_InitStruct.Pull = LL_GPIO_PULL_NO;
  LL_GPIO_Init(EEPROM_WP_GPIO_Port, &GPIO_InitStruct);

  /**/
  GPIO_InitStruct.Pin = MCU_CURR_SENS_1kR_Pin;
  GPIO_InitStruct.Mode = LL_GPIO_MODE_OUTPUT;
  GPIO_InitStruct.Speed = LL_GPIO_SPEED_FREQ_LOW;
  GPIO_InitStruct.OutputType = LL_GPIO_OUTPUT_PUSHPULL;
  GPIO_InitStruct.Pull = LL_GPIO_PULL_NO;
  LL_GPIO_Init(MCU_CURR_SENS_1kR_GPIO_Port, &GPIO_InitStruct);

  /**/
  GPIO_InitStruct.Pin = MCU_CURR_SENS_100R_Pin;
  GPIO_InitStruct.Mode = LL_GPIO_MODE_OUTPUT;
  GPIO_InitStruct.Speed = LL_GPIO_SPEED_FREQ_LOW;
  GPIO_InitStruct.OutputType = LL_GPIO_OUTPUT_PUSHPULL;
  GPIO_InitStruct.Pull = LL_GPIO_PULL_NO;
  LL_GPIO_Init(MCU_CURR_SENS_100R_GPIO_Port, &GPIO_InitStruct);

  /**/
  GPIO_InitStruct.Pin = MCU_CURR_SENS_10R_Pin;
  GPIO_InitStruct.Mode = LL_GPIO_MODE_OUTPUT;
  GPIO_InitStruct.Speed = LL_GPIO_SPEED_FREQ_LOW;
  GPIO_InitStruct.OutputType = LL_GPIO_OUTPUT_PUSHPULL;
  GPIO_InitStruct.Pull = LL_GPIO_PULL_NO;
  LL_GPIO_Init(MCU_CURR_SENS_10R_GPIO_Port, &GPIO_InitStruct);

  /**/
  GPIO_InitStruct.Pin = MCU_CURR_SENS_1R_Pin;
  GPIO_InitStruct.Mode = LL_GPIO_MODE_OUTPUT;
  GPIO_InitStruct.Speed = LL_GPIO_SPEED_FREQ_LOW;
  GPIO_InitStruct.OutputType = LL_GPIO_OUTPUT_PUSHPULL;
  GPIO_InitStruct.Pull = LL_GPIO_PULL_NO;
  LL_GPIO_Init(MCU_CURR_SENS_1R_GPIO_Port, &GPIO_InitStruct);

  /**/
  GPIO_InitStruct.Pin = DAC1_nRST_Pin;
  GPIO_InitStruct.Mode = LL_GPIO_MODE_OUTPUT;
  GPIO_InitStruct.Speed = LL_GPIO_SPEED_FREQ_LOW;
  GPIO_InitStruct.OutputType = LL_GPIO_OUTPUT_PUSHPULL;
  GPIO_InitStruct.Pull = LL_GPIO_PULL_NO;
  LL_GPIO_Init(DAC1_nRST_GPIO_Port, &GPIO_InitStruct);

  /**/
  GPIO_InitStruct.Pin = DAC1_LDAC_Pin;
  GPIO_InitStruct.Mode = LL_GPIO_MODE_OUTPUT;
  GPIO_InitStruct.Speed = LL_GPIO_SPEED_FREQ_LOW;
  GPIO_InitStruct.OutputType = LL_GPIO_OUTPUT_PUSHPULL;
  GPIO_InitStruct.Pull = LL_GPIO_PULL_NO;
  LL_GPIO_Init(DAC1_LDAC_GPIO_Port, &GPIO_InitStruct);

  /**/
  GPIO_InitStruct.Pin = SPI3_NSS_Pin;
  GPIO_InitStruct.Mode = LL_GPIO_MODE_OUTPUT;
  GPIO_InitStruct.Speed = LL_GPIO_SPEED_FREQ_LOW;
  GPIO_InitStruct.OutputType = LL_GPIO_OUTPUT_PUSHPULL;
  GPIO_InitStruct.Pull = LL_GPIO_PULL_NO;
  LL_GPIO_Init(SPI3_NSS_GPIO_Port, &GPIO_InitStruct);

  /**/
  GPIO_InitStruct.Pin = ADC1_RVS1_Pin;
  GPIO_InitStruct.Mode = LL_GPIO_MODE_INPUT;
  GPIO_InitStruct.Pull = LL_GPIO_PULL_NO;
  LL_GPIO_Init(ADC1_RVS1_GPIO_Port, &GPIO_InitStruct);

  /**/
  GPIO_InitStruct.Pin = ADC1_RVS2_Pin;
  GPIO_InitStruct.Mode = LL_GPIO_MODE_INPUT;
  GPIO_InitStruct.Pull = LL_GPIO_PULL_NO;
  LL_GPIO_Init(ADC1_RVS2_GPIO_Port, &GPIO_InitStruct);

  /**/
  GPIO_InitStruct.Pin = DAC2_nLDAC_Pin;
  GPIO_InitStruct.Mode = LL_GPIO_MODE_OUTPUT;
  GPIO_InitStruct.Speed = LL_GPIO_SPEED_FREQ_HIGH;
  GPIO_InitStruct.OutputType = LL_GPIO_OUTPUT_PUSHPULL;
  GPIO_InitStruct.Pull = LL_GPIO_PULL_NO;
  LL_GPIO_Init(DAC2_nLDAC_GPIO_Port, &GPIO_InitStruct);

  /**/
  LL_SYSCFG_SetEXTISource(LL_SYSCFG_EXTI_PORTE, LL_SYSCFG_EXTI_LINE7);

  /**/
  LL_SYSCFG_SetEXTISource(LL_SYSCFG_EXTI_PORTD, LL_SYSCFG_EXTI_LINE9);

  /**/
  LL_SYSCFG_SetEXTISource(LL_SYSCFG_EXTI_PORTD, LL_SYSCFG_EXTI_LINE10);

  /**/
  LL_SYSCFG_SetEXTISource(LL_SYSCFG_EXTI_PORTD, LL_SYSCFG_EXTI_LINE11);

  /**/
  EXTI_InitStruct.Line_0_31 = LL_EXTI_LINE_7;
  EXTI_InitStruct.LineCommand = ENABLE;
  EXTI_InitStruct.Mode = LL_EXTI_MODE_IT;
  EXTI_InitStruct.Trigger = LL_EXTI_TRIGGER_RISING;
  LL_EXTI_Init(&EXTI_InitStruct);

  /**/
  EXTI_InitStruct.Line_0_31 = LL_EXTI_LINE_9;
  EXTI_InitStruct.LineCommand = ENABLE;
  EXTI_InitStruct.Mode = LL_EXTI_MODE_IT;
  EXTI_InitStruct.Trigger = LL_EXTI_TRIGGER_RISING;
  LL_EXTI_Init(&EXTI_InitStruct);

  /**/
  EXTI_InitStruct.Line_0_31 = LL_EXTI_LINE_10;
  EXTI_InitStruct.LineCommand = ENABLE;
  EXTI_InitStruct.Mode = LL_EXTI_MODE_IT;
  EXTI_InitStruct.Trigger = LL_EXTI_TRIGGER_RISING;
  LL_EXTI_Init(&EXTI_InitStruct);

  /**/
  EXTI_InitStruct.Line_0_31 = LL_EXTI_LINE_11;
  EXTI_InitStruct.LineCommand = ENABLE;
  EXTI_InitStruct.Mode = LL_EXTI_MODE_IT;
  EXTI_InitStruct.Trigger = LL_EXTI_TRIGGER_RISING;
  LL_EXTI_Init(&EXTI_InitStruct);

  /**/
  LL_GPIO_SetPinPull(TRIG_IN_GPIO_Port, TRIG_IN_Pin, LL_GPIO_PULL_NO);

  /**/
  LL_GPIO_SetPinPull(MCU_nTDS_GPIO_Port, MCU_nTDS_Pin, LL_GPIO_PULL_NO);

  /**/
  LL_GPIO_SetPinPull(MCU_nISNK_GPIO_Port, MCU_nISNK_Pin, LL_GPIO_PULL_NO);

  /**/
  LL_GPIO_SetPinPull(MCU_nISRC_GPIO_Port, MCU_nISRC_Pin, LL_GPIO_PULL_NO);

  /**/
  LL_GPIO_SetPinMode(TRIG_IN_GPIO_Port, TRIG_IN_Pin, LL_GPIO_MODE_INPUT);

  /**/
  LL_GPIO_SetPinMode(MCU_nTDS_GPIO_Port, MCU_nTDS_Pin, LL_GPIO_MODE_INPUT);

  /**/
  LL_GPIO_SetPinMode(MCU_nISNK_GPIO_Port, MCU_nISNK_Pin, LL_GPIO_MODE_INPUT);

  /**/
  LL_GPIO_SetPinMode(MCU_nISRC_GPIO_Port, MCU_nISRC_Pin, LL_GPIO_MODE_INPUT);

}

void StartDefaultTask(void *argument)
{
  /* init code for LWIP */
  MX_LWIP_Init();
  /* USER CODE BEGIN 5 */
  /* Infinite loop */
  for(;;)
  {
    osDelay(10);
  }
  /* USER CODE END 5 */
}

void StartLEDTask(void *argument)
{
  /* USER CODE BEGIN StartLEDTask */
  /* Infinite loop */

	uint8_t  led_color = GREEN, tmp = GREEN;
	osStatus_t status;

  for(;;)
  {
	  status = osMessageQueueGet(QueueLEDHandle, &led_color, NULL, 0U);

	  if(osOK == status)
	  {
		  tmp = led_color;
	  }
	  else
	  {
		  led_color = tmp;
	  }

	  switch(led_color)
	  {
	  	  case RED: LL_GPIO_TogglePin(LED_RED_GPIO_Port, LED_RED_Pin); break;
	  	  case GREEN: LL_GPIO_TogglePin(LED_GREEN_GPIO_Port, LED_GREEN_Pin); break;
	  	  case BLUE: LL_GPIO_TogglePin(LED_BLUE_GPIO_Port, LED_BLUE_Pin); break;
	  	  default: LL_GPIO_TogglePin(LED_RED_GPIO_Port, LED_RED_Pin); break;
	  }

	  osDelay(pdMS_TO_TICKS(1000));
  }
  /* USER CODE END StartLEDTask */
}

void StartTriggerTask(void *argument)
{
  for(;;)
  {
    osDelay(1);
  }
}

void HAL_TIM_PeriodElapsedCallback(TIM_HandleTypeDef *htim)
{
  if (htim->Instance == TIM2) {
    HAL_IncTick();
  }
}

void Error_Handler(void)
{
  __disable_irq();
  while (1)
  {
  }
}
